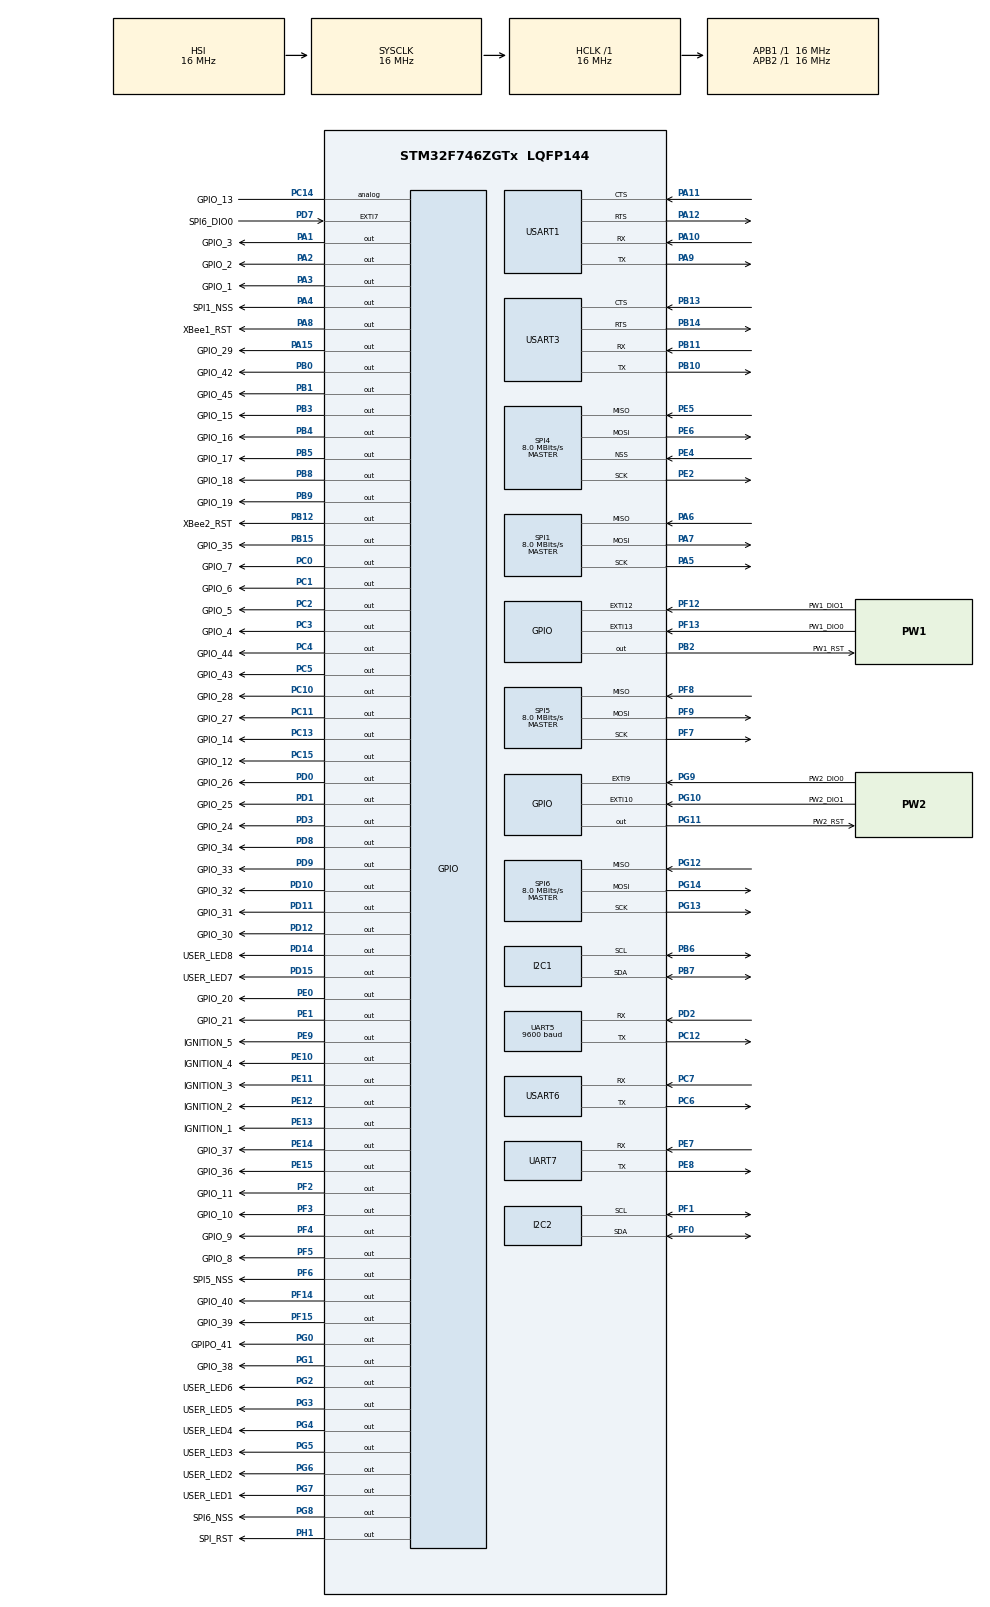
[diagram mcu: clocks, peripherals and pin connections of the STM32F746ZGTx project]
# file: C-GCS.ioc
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Mcu.Family=STM32F7
Mcu.Name=STM32F746ZGTx
Mcu.Package=LQFP144
NVIC.EXTI15_10_IRQn=true\:0\:0\:false\:false\:true\:true\:true\:true
NVIC.EXTI9_5_IRQn=true\:0\:0\:false\:false\:true\:true\:true\:true
NVIC.PriorityGroup=NVIC_PRIORITYGROUP_4
NVIC.SPI1_IRQn=true\:0\:0\:false\:false\:true\:true\:true\:true
NVIC.SPI6_IRQn=true\:0\:0\:false\:false\:true\:true\:true\:true
NVIC.UART5_IRQn=true\:0\:0\:false\:false\:true\:true\:true\:true
NVIC.UART7_IRQn=true\:0\:0\:false\:false\:true\:true\:true\:true
PA0/WKUP.Mode=SYS_WakeUp0
PA0/WKUP.Signal=SYS_WKUP1
PA1.GPIO_Label=GPIO_3
PA1.Signal=GPIO_Output
PA10.Mode=Asynchronous
PA10.Signal=USART1_RX
PA11.Mode=CTS_RTS
PA11.Signal=USART1_CTS
PA12.Mode=CTS_RTS
PA12.Signal=USART1_RTS
PA13.Mode=Serial_Wire
PA13.Signal=SYS_JTMS-SWDIO
PA14.Mode=Serial_Wire
PA14.Signal=SYS_JTCK-SWCLK
PA15.GPIO_Label=GPIO_29
PA15.Signal=GPIO_Output
PA2.GPIO_Label=GPIO_2
PA2.Signal=GPIO_Output
PA3.GPIO_Label=GPIO_1
PA3.Signal=GPIO_Output
PA4.GPIO_Label=SPI1_NSS
PA4.GPIO_PuPd=GPIO_NOPULL
PA4.PinState=GPIO_PIN_SET
PA4.Signal=GPIO_Output
PA5.Mode=Full_Duplex_Master
PA5.Signal=SPI1_SCK
PA6.Mode=Full_Duplex_Master
PA6.Signal=SPI1_MISO
PA7.Mode=Full_Duplex_Master
PA7.Signal=SPI1_MOSI
PA8.GPIO_Label=XBee1_RST
PA8.Signal=GPIO_Output
PA9.Mode=Asynchronous
PA9.Signal=USART1_TX
PB0.GPIO_Label=GPIO_42
PB0.Signal=GPIO_Output
PB1.GPIO_Label=GPIO_45
PB1.Signal=GPIO_Output
PB10.Mode=Asynchronous
PB10.Signal=USART3_TX
PB11.Mode=Asynchronous
PB11.Signal=USART3_RX
PB12.GPIO_Label=XBee2_RST
PB12.Signal=GPIO_Output
PB13.Mode=CTS_RTS
PB13.Signal=USART3_CTS
PB14.Mode=CTS_RTS
PB14.Signal=USART3_RTS
PB15.GPIO_Label=GPIO_35
PB15.Signal=GPIO_Output
PB2.GPIO_Label=PW1_RST
PB2.PinState=GPIO_PIN_RESET
PB2.Signal=GPIO_Output
PB3.GPIO_Label=GPIO_15
PB3.Signal=GPIO_Output
PB4.GPIO_Label=GPIO_16
PB4.Signal=GPIO_Output
PB5.GPIO_Label=GPIO_17
PB5.Signal=GPIO_Output
PB6.Mode=I2C
PB6.Signal=I2C1_SCL
PB7.Mode=I2C
PB7.Signal=I2C1_SDA
PB8.GPIO_Label=GPIO_18
PB8.Signal=GPIO_Output
PB9.GPIO_Label=GPIO_19
PB9.Signal=GPIO_Output
PC0.GPIO_Label=GPIO_7
PC0.Signal=GPIO_Output
PC1.GPIO_Label=GPIO_6
PC1.Signal=GPIO_Output
PC10.GPIO_Label=GPIO_28
PC10.Signal=GPIO_Output
PC11.GPIO_Label=GPIO_27
PC11.Signal=GPIO_Output
PC12.Mode=Asynchronous
PC12.Signal=UART5_TX
PC13.GPIO_Label=GPIO_14
PC13.Signal=GPIO_Output
PC14/OSC32_IN.GPIO_Label=GPIO_13
PC14/OSC32_IN.Signal=GPIO_Analog
PC15/OSC32_OUT.GPIO_Label=GPIO_12
PC15/OSC32_OUT.Signal=GPIO_Output
PC2.GPIO_Label=GPIO_5
PC2.Signal=GPIO_Output
PC3.GPIO_Label=GPIO_4
PC3.Signal=GPIO_Output
PC4.GPIO_Label=GPIO_44
PC4.Signal=GPIO_Output
PC5.GPIO_Label=GPIO_43
PC5.Signal=GPIO_Output
PC6.Mode=Asynchronous
PC6.Signal=USART6_TX
PC7.Mode=Asynchronous
PC7.Signal=USART6_RX
PD0.GPIO_Label=GPIO_26
PD0.Signal=GPIO_Output
PD1.GPIO_Label=GPIO_25
PD1.Signal=GPIO_Output
PD10.GPIO_Label=GPIO_32
PD10.Signal=GPIO_Output
PD11.GPIO_Label=GPIO_31
PD11.Signal=GPIO_Output
PD12.GPIO_Label=GPIO_30
PD12.Signal=GPIO_Output
PD14.GPIO_Label=USER_LED8
PD14.Signal=GPIO_Output
PD15.GPIO_Label=USER_LED7
PD15.Signal=GPIO_Output
PD2.Mode=Asynchronous
PD2.Signal=UART5_RX
PD3.GPIO_Label=GPIO_24
PD3.Signal=GPIO_Output
PD5.Signal=USART2_TX
PD6.Signal=USART2_RX
PD7.GPIO_Label=SPI6_DIO0
PD7.Signal=GPXTI7
PD8.GPIO_Label=GPIO_34
PD8.Signal=GPIO_Output
PD9.GPIO_Label=GPIO_33
PD9.Signal=GPIO_Output
PE0.GPIO_Label=GPIO_20
PE0.Signal=GPIO_Output
PE1.GPIO_Label=GPIO_21
PE1.Signal=GPIO_Output
PE10.GPIO_Label=IGNITION_4
PE10.Signal=GPIO_Output
PE11.GPIO_Label=IGNITION_3
PE11.Signal=GPIO_Output
PE12.GPIO_Label=IGNITION_2
PE12.Signal=GPIO_Output
PE13.GPIO_Label=IGNITION_1
PE13.Signal=GPIO_Output
PE14.GPIO_Label=GPIO_37
PE14.Signal=GPIO_Output
PE15.GPIO_Label=GPIO_36
PE15.Signal=GPIO_Output
PE2.Mode=Full_Duplex_Master
PE2.Signal=SPI4_SCK
PE4.Mode=NSS_Signal_Hard_Input
PE4.Signal=SPI4_NSS
PE5.Mode=Full_Duplex_Master
PE5.Signal=SPI4_MISO
PE6.Mode=Full_Duplex_Master
PE6.Signal=SPI4_MOSI
PE7.Mode=Asynchronous
PE7.Signal=UART7_RX
PE8.Mode=Asynchronous
PE8.Signal=UART7_TX
PE9.GPIO_Label=IGNITION_5
PE9.Signal=GPIO_Output
PF0.Mode=I2C
PF0.Signal=I2C2_SDA
PF1.Mode=I2C
PF1.Signal=I2C2_SCL
PF12.GPIO_Label=PW1_DIO1
PF12.Signal=GPXTI12
PF13.GPIO_Label=PW1_DIO0
PF13.Signal=GPXTI13
PF14.GPIO_Label=GPIO_40
PF14.Signal=GPIO_Output
PF15.GPIO_Label=GPIO_39
PF15.Signal=GPIO_Output
PF2.GPIO_Label=GPIO_11
PF2.Signal=GPIO_Output
PF3.GPIO_Label=GPIO_10
PF3.Signal=GPIO_Output
PF4.GPIO_Label=GPIO_9
PF4.Signal=GPIO_Output
PF5.GPIO_Label=GPIO_8
PF5.Signal=GPIO_Output
PF6.GPIO_Label=SPI5_NSS
PF6.Signal=GPIO_Output
PF7.Mode=Full_Duplex_Master
PF7.Signal=SPI5_SCK
PF8.Mode=Full_Duplex_Master
PF8.Signal=SPI5_MISO
PF9.Mode=Full_Duplex_Master
PF9.Signal=SPI5_MOSI
PG0.GPIO_Label=GPIPO_41
PG0.Signal=GPIO_Output
PG1.GPIO_Label=GPIO_38
PG1.Signal=GPIO_Output
PG10.GPIO_Label=PW2_DIO1
PG10.Signal=GPXTI10
PG11.GPIO_Label=PW2_RST
PG11.Signal=GPIO_Output
PG12.Mode=Full_Duplex_Master
PG12.Signal=SPI6_MISO
PG13.Mode=Full_Duplex_Master
PG13.Signal=SPI6_SCK
PG14.Mode=Full_Duplex_Master
PG14.Signal=SPI6_MOSI
PG2.GPIO_Label=USER_LED6
PG2.Signal=GPIO_Output
PG3.GPIO_Label=USER_LED5
PG3.Signal=GPIO_Output
PG4.GPIO_Label=USER_LED4
PG4.Signal=GPIO_Output
PG5.GPIO_Label=USER_LED3
PG5.Signal=GPIO_Output
PG6.GPIO_Label=USER_LED2
PG6.Signal=GPIO_Output
PG7.GPIO_Label=USER_LED1
PG7.Signal=GPIO_Output
PG8.GPIO_Label=SPI6_NSS
PG8.Signal=GPIO_Output
PG9.GPIO_Label=PW2_DIO0
PG9.Signal=GPXTI9
PH0/OSC_IN.Signal=RCC_OSC_IN
PH1/OSC_OUT.GPIO_Label=SPI_RST
PH1/OSC_OUT.Signal=GPIO_Output
ProjectManager.HeapSize=0x200
ProjectManager.StackSize=0x400
ProjectManager.TargetToolchain=STM32CubeIDE
RCC.AHBFreq_Value=16000000
RCC.APB1Freq_Value=16000000
RCC.APB1TimFreq_Value=16000000
RCC.APB2Freq_Value=16000000
RCC.APB2TimFreq_Value=16000000
RCC.CortexFreq_Value=16000000
RCC.HCLKFreq_Value=16000000
RCC.HSE_VALUE=25000000
RCC.HSI_VALUE=16000000
RCC.LSE_VALUE=32768
RCC.PLLM=12
RCC.PLLN=50
RCC.SYSCLKFreq_VALUE=16000000
RCC.USBFreq_Value=33333333.333333332
RCC.VCOOutputFreq_Value=66666666.666666664
SPI1.CalculateBaudRate=8.0 MBits/s
SPI1.DataSize=SPI_DATASIZE_8BIT
SPI1.Direction=SPI_DIRECTION_2LINES
SPI1.Mode=SPI_MODE_MASTER
SPI1.VirtualType=VM_MASTER
SPI4.BaudRatePrescaler=SPI_BAUDRATEPRESCALER_2
SPI4.CalculateBaudRate=8.0 MBits/s
SPI4.Direction=SPI_DIRECTION_2LINES
SPI4.Mode=SPI_MODE_MASTER
SPI4.VirtualNSS=VM_NSSHARD
SPI4.VirtualType=VM_MASTER
SPI5.BaudRatePrescaler=SPI_BAUDRATEPRESCALER_2
SPI5.CalculateBaudRate=8.0 MBits/s
SPI5.Direction=SPI_DIRECTION_2LINES
SPI5.Mode=SPI_MODE_MASTER
SPI5.VirtualType=VM_MASTER
SPI6.BaudRatePrescaler=SPI_BAUDRATEPRESCALER_2
SPI6.CalculateBaudRate=8.0 MBits/s
SPI6.DataSize=SPI_DATASIZE_8BIT
SPI6.Direction=SPI_DIRECTION_2LINES
SPI6.Mode=SPI_MODE_MASTER
SPI6.VirtualType=VM_MASTER
UART5.BaudRate=9600
USART1.VirtualMode-Asynchronous=VM_ASYNC
USART3.VirtualMode-Asynchronous=VM_ASYNC
USART6.VirtualMode-Asynchronous=VM_ASYNC
board=custom

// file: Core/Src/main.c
/* USER CODE BEGIN Header */
/**
 ******************************************************************************
 * @file           : main.c
 * @brief          : Main program body
 ******************************************************************************
 * @attention
 *
 * Copyright (c) 2023 STMicroelectronics.
 * All rights reserved.
 *
 * This software is licensed under terms that can be found in the LICENSE file
 * in the root directory of this software component.
 * If no LICENSE file comes with this software, it is provided AS-IS.
 *
 ******************************************************************************
 */
/* USER CODE END Header */
#include "main.h"
#include "i2c.h"
#include "spi.h"
#include "usart.h"
#include "gpio.h"

/* USER CODE BEGIN Includes */

#include "gps.h"

#include "system.h"
/* USER CODE END Includes */

/* USER CODE BEGIN PD */

uint8_t loraReceiveBuffer[41];
extern LoRa myLoRa;
extern LoRa myLoRaT;

uint8_t rx_data1;
uint8_t tx_data[] = {"patates"};
/* USER CODE END PD */

void SystemClock_Config(void);

/* USER CODE BEGIN 0 */
HAL_UART_RxCpltCallback(UART_HandleTypeDef *huart)
{
  if (huart->Instance == huart5.Instance)
    GPS_CallBack();
}

HAL_GPIO_EXTI_Callback(uint16_t GPIO_PIN)
{

//  if (GPIO_PIN == PW1_DIO0_Pin){
//	  ParseAkuLoRaData();
//
//  }
//  else if (GPIO_PIN == PW2_DIO0_Pin){
//    loraAkuRecevice();
//  	ParseAkuLoRaData();

  loraArtamRecevice();
  ParseArtamLoRaData();

}

/* USER CODE END 0 */

int main(void)
{

  /* MCU Configuration--------------------------------------------------------*/

  /* Reset of all peripherals, Initializes the Flash interface and the Systick. */
  HAL_Init();

  /* Configure the system clock */
  SystemClock_Config();

  /* Initialize all configured peripherals */
  MX_GPIO_Init();
  MX_SPI1_Init();
  MX_SPI6_Init();
  MX_UART7_Init();
  MX_USART1_UART_Init();
  MX_USART3_UART_Init();
  MX_SPI4_Init();
  MX_I2C1_Init();
  MX_I2C2_Init();
  MX_SPI5_Init();
  MX_UART5_Init();
  MX_USART6_UART_Init();
  /* USER CODE BEGIN 2 */
  //GPS_Init();
  initLoRa();
  HAL_GPIO_WritePin(USER_LED1_GPIO_Port, USER_LED1_Pin, 1);
  HAL_Delay(500);
  initLoRaT();
  HAL_GPIO_WritePin(USER_LED2_GPIO_Port, USER_LED2_Pin, 1);

  /* USER CODE END 2 */

  /* Infinite loop */
  /* USER CODE BEGIN WHILE */
  while (1)
  {
//	HAL_UART_Transmit_IT(&huart7, "hello world \n", 12);
//	HAL_Delay(500);
    //LoRa_transmit(&myLoRaT, tx_data, sizeof(tx_data), 1000);
    //HAL_Delay(100);
    //LoRa_transmit(&myLoRa, tx_data, sizeof(tx_data), 1000);
    //HAL_Delay(10);

    /*
      HAL_GPIO_WritePin(USER_LED1_GPIO_Port, USER_LED1_Pin, 1);
      HAL_Delay(10);
      HAL_GPIO_WritePin(USER_LED1_GPIO_Port, USER_LED1_Pin, 0);
      HAL_Delay(10);
      HAL_GPIO_WritePin(USER_LED2_GPIO_Port, USER_LED2_Pin, 1);
      HAL_Delay(10);
      HAL_GPIO_WritePin(USER_LED2_GPIO_Port, USER_LED2_Pin, 0);
      HAL_Delay(10);
      HAL_GPIO_WritePin(USER_LED3_GPIO_Port, USER_LED3_Pin, 1);
      HAL_Delay(10);
      HAL_GPIO_WritePin(USER_LED3_GPIO_Port, USER_LED3_Pin, 0);
      HAL_Delay(10);
      HAL_GPIO_WritePin(USER_LED4_GPIO_Port, USER_LED4_Pin, 1);
      HAL_Delay(10);
      HAL_GPIO_WritePin(USER_LED4_GPIO_Port, USER_LED4_Pin, 0);
      HAL_Delay(10);
      HAL_GPIO_WritePin(USER_LED5_GPIO_Port, USER_LED5_Pin, 1);
      HAL_Delay(10);
      HAL_GPIO_WritePin(USER_LED5_GPIO_Port, USER_LED5_Pin, 0);
      HAL_Delay(10);
      HAL_GPIO_WritePin(USER_LED6_GPIO_Port, USER_LED6_Pin, 1);
      HAL_Delay(10);
      HAL_GPIO_WritePin(USER_LED6_GPIO_Port, USER_LED6_Pin, 0);
      HAL_Delay(10);
      HAL_GPIO_WritePin(USER_LED7_GPIO_Port, USER_LED7_Pin, 1);
      HAL_Delay(10);
      HAL_GPIO_WritePin(USER_LED7_GPIO_Port, USER_LED7_Pin, 0);
      HAL_Delay(10);
      HAL_GPIO_WritePin(USER_LED8_GPIO_Port, USER_LED8_Pin, 1);
      HAL_Delay(10);
      HAL_GPIO_WritePin(USER_LED8_GPIO_Port, USER_LED8_Pin, 0);
      HAL_Delay(10);
      HAL_GPIO_WritePin(USER_LED7_GPIO_Port, USER_LED7_Pin, 1);
      HAL_Delay(10);
      HAL_GPIO_WritePin(USER_LED7_GPIO_Port, USER_LED7_Pin, 0);
      HAL_Delay(10);
      HAL_GPIO_WritePin(USER_LED6_GPIO_Port, USER_LED6_Pin, 1);
      HAL_Delay(10);
      HAL_GPIO_WritePin(USER_LED6_GPIO_Port, USER_LED6_Pin, 0);
      HAL_Delay(10);
      HAL_GPIO_WritePin(USER_LED5_GPIO_Port, USER_LED5_Pin, 1);
      HAL_Delay(10);
      HAL_GPIO_WritePin(USER_LED5_GPIO_Port, USER_LED5_Pin, 0);
      HAL_Delay(10);
      HAL_GPIO_WritePin(USER_LED4_GPIO_Port, USER_LED4_Pin, 1);
      HAL_Delay(10);
      HAL_GPIO_WritePin(USER_LED4_GPIO_Port, USER_LED4_Pin, 0);
      HAL_Delay(10);
      HAL_GPIO_WritePin(USER_LED3_GPIO_Port, USER_LED3_Pin, 1);
      HAL_Delay(10);
      HAL_GPIO_WritePin(USER_LED3_GPIO_Port, USER_LED3_Pin, 0);
      HAL_Delay(10);
      HAL_GPIO_WritePin(USER_LED2_GPIO_Port, USER_LED2_Pin, 1);
      HAL_Delay(10);
      HAL_GPIO_WritePin(USER_LED2_GPIO_Port, USER_LED2_Pin, 0);
    */

    /* USER CODE END WHILE */

  }
}

void SystemClock_Config(void)
{
  RCC_OscInitTypeDef RCC_OscInitStruct = {0};
  RCC_ClkInitTypeDef RCC_ClkInitStruct = {0};

  /** Configure the main internal regulator output voltage
  */
  __HAL_RCC_PWR_CLK_ENABLE();
  __HAL_PWR_VOLTAGESCALING_CONFIG(PWR_REGULATOR_VOLTAGE_SCALE3);

  /** Initializes the RCC Oscillators according to the specified parameters
  * in the RCC_OscInitTypeDef structure.
  */
  RCC_OscInitStruct.OscillatorType = RCC_OSCILLATORTYPE_HSI;
  RCC_OscInitStruct.HSIState = RCC_HSI_ON;
  RCC_OscInitStruct.HSICalibrationValue = RCC_HSICALIBRATION_DEFAULT;
  RCC_OscInitStruct.PLL.PLLState = RCC_PLL_NONE;
  if (HAL_RCC_OscConfig(&RCC_OscInitStruct) != HAL_OK)
  {
    Error_Handler();
  }

  /** Initializes the CPU, AHB and APB buses clocks
  */
  RCC_ClkInitStruct.ClockType = RCC_CLOCKTYPE_HCLK|RCC_CLOCKTYPE_SYSCLK
                              |RCC_CLOCKTYPE_PCLK1|RCC_CLOCKTYPE_PCLK2;
  RCC_ClkInitStruct.SYSCLKSource = RCC_SYSCLKSOURCE_HSI;
  RCC_ClkInitStruct.AHBCLKDivider = RCC_SYSCLK_DIV1;
  RCC_ClkInitStruct.APB1CLKDivider = RCC_HCLK_DIV1;
  RCC_ClkInitStruct.APB2CLKDivider = RCC_HCLK_DIV1;

  if (HAL_RCC_ClockConfig(&RCC_ClkInitStruct, FLASH_LATENCY_0) != HAL_OK)
  {
    Error_Handler();
  }
}

void Error_Handler(void)
{
  __disable_irq();
  while (1)
  {
  }
}
